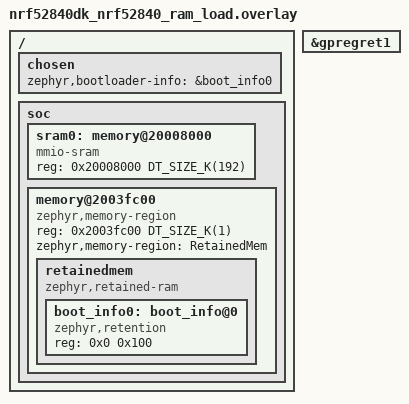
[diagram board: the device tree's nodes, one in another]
/delete-node/ &sram0;

/*
 * Layout must match the nrf52840dk_nrf52840_ram_load overlay file within mcuboot
 * application configuration directory
 */

&gpregret1 {
	/delete-node/ boot_mode@0;
};

/ {
	chosen {
		/delete-property/ zephyr,boot-mode;
		/delete-property/ zephyr,code-partition;
		zephyr,bootloader-info = &boot_info0;
	};

	soc {
		sram0: memory@20008000 {
			compatible = "mmio-sram";
			reg = <0x20008000 DT_SIZE_K(192)>;
		};

		memory@2003fc00 {
			compatible = "zephyr,memory-region", "mmio-sram";
			reg = <0x2003fc00 DT_SIZE_K(1)>;
			ranges = <0x0 0x2003fc00 DT_SIZE_K(1)>;
			zephyr,memory-region = "RetainedMem";
			status = "okay";
			#address-cells = <1>;
			#size-cells = <1>;

			retainedmem {
				compatible = "zephyr,retained-ram";
				status = "okay";
				ranges;
				#address-cells = <1>;
				#size-cells = <1>;

				boot_info0: boot_info@0 {
					compatible = "zephyr,retention";
					status = "okay";
					reg = <0x0 0x100>;
				};
			};
		};
	};
};
